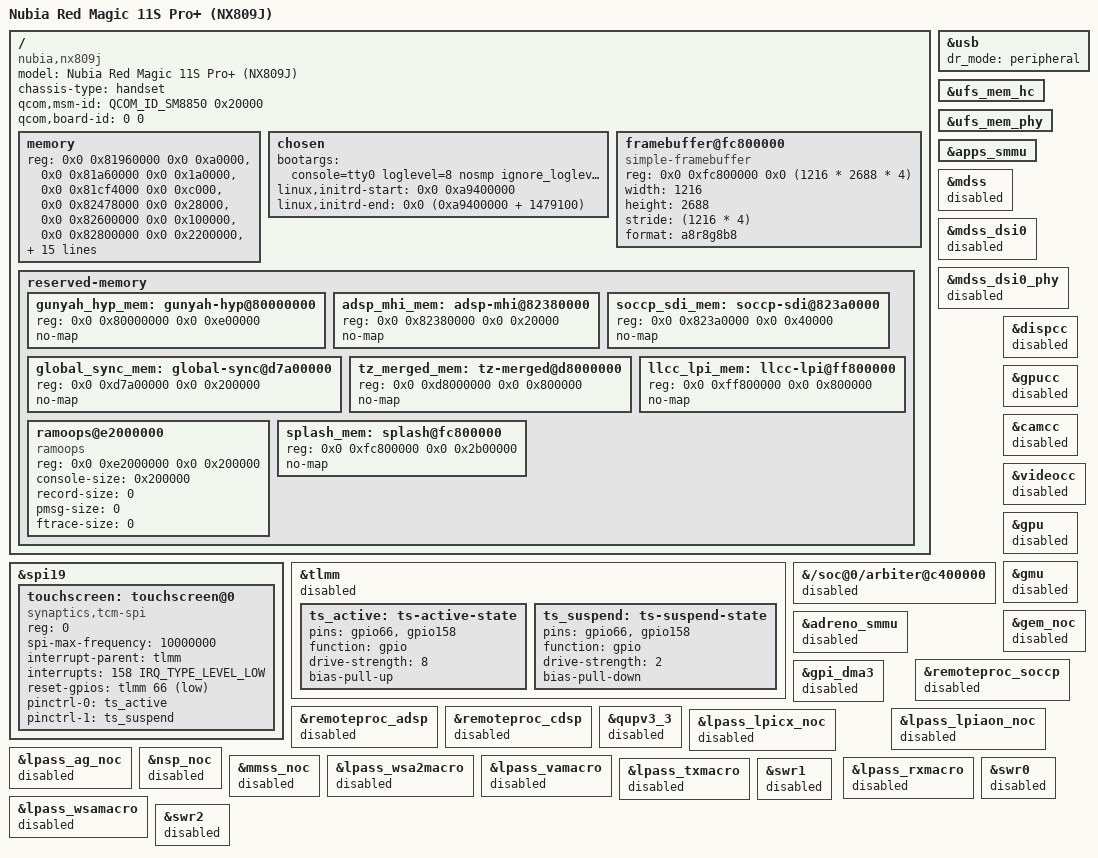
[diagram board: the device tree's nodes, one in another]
// SPDX-License-Identifier: BSD-3-Clause
/*
 * Copyright (c) 2026 Nubia / ZTE. All rights reserved.
 *
 * Nubia Red Magic 11S Pro+ (NX809J)
 * SoC: Qualcomm SM8850 (mainline codename: kaanapali)
 */

/dts-v1/;

#include <dt-bindings/arm/qcom,ids.h>
#include <dt-bindings/gpio/gpio.h>
#include <dt-bindings/interrupt-controller/irq.h>
#include "kaanapali-mtp.dts"

/*
 * No PSCI probe on this phone.
 *
 * kaanapali.dtsi declares a PSCI node with method = "smc". The vendor
 * devicetree for this board has no /psci node at all: the bootloader starts
 * Gunyah as the hypervisor and Android runs as a guest whose PSCI comes from
 * Gunyah over HVC - the tree carries /hypervisor with
 * "qcom,gunyah-hypervisor-1.0" plus a "qcom,gunyah-vm" child instead. Probing
 * the SMC conduit hands EL3 an SMC the firmware was never configured to
 * accept, and the answer to that is a reset into the vendor's memory dump,
 * before the kernel has printed a single line. Boot single core and leave the
 * secure monitor alone until we know what it does implement.
 */
/ {
	/delete-node/ psci;
};

/ {
	model = "Nubia Red Magic 11S Pro+ (NX809J)";
	compatible = "nubia,nx809j", "qcom,kaanapali-mtp", "qcom,kaanapali";

	chassis-type = "handset";

	/* Bootloader board selection - REQUIRED. Without these the bootloader
	 * cannot choose the correct board and does not bring the platform up.
	 * Mirrors the working kaanapali trees (oneplus-infiniti). */
	qcom,msm-id = <QCOM_ID_SM8850 0x20000>;	/* SM8850 v2.0 */
	qcom,board-id = <0 0>;

	/* /memory: filled by ABL when booting through ABL (the bootloader
	 * replaces /memory with the real usable-RAM map, so the ranges below
	 * cost nothing there), but U-Boot - the path this board is now brought
	 * up on - hands the kernel exactly the devicetree it loaded, so the
	 * ranges have to be here or the kernel has no RAM at all.
	 *
	 * They are ABL's own usable ranges, read back from this device
	 * (/sys/firmware/fdt on a stock Android boot) - not a guess.
	 *
	 * NOTE the 0xdfda0000 range: ABL reports it as one run up to
	 * 0xff800000, but the splash carve-out [0xfc800000, 0xff300000) is
	 * split OUT here instead of merely being covered by reserved-memory.
	 * simplefb does request_mem_region() on its framebuffer, and a region
	 * that sits inside the busy "System RAM" iomem resource fails that
	 * request with -EBUSY - so the console would silently never appear.
	 * Keeping the framebuffer out of /memory also guarantees nothing
	 * allocates over the buffer the DPU is still scanning. */
	memory {
		device_type = "memory";
		reg = <0x0 0x81960000 0x0 0xa0000>,
		      <0x0 0x81a60000 0x0 0x1a0000>,
		      <0x0 0x81cf4000 0x0 0xc000>,
		      <0x0 0x82478000 0x0 0x28000>,
		      <0x0 0x82600000 0x0 0x100000>,
		      <0x0 0x82800000 0x0 0x2200000>,
		      <0x0 0x8a980000 0x0 0x80000>,
		      <0x0 0x9959c000 0x0 0x64000>,
		      <0x0 0x9ce80000 0x0 0x2e00000>,
		      <0x0 0x9ffe0000 0x0 0x70000>,
		      <0x0 0xa0910000 0x0 0xa70000>,
		      <0x0 0xa5a00000 0x0 0x2f423000>,
		      <0x0 0xd5100000 0x0 0x2700000>,
		      <0x0 0xd79c0000 0x0 0x40000>,
		      <0x0 0xd7c00000 0x0 0x400000>,
		      <0x0 0xdfda0000 0x0 0x1ca60000>,	/* .. 0xfc800000 */
		      <0x0 0xff300000 0x0 0x500000>,	/* 0xff300000 .. 0xff800000 */
		      <0x8 0x80000000 0x0 0x2f6fd000>,
		      <0x8 0xb0000000 0x0 0x8500000>,
		      <0x8 0xc0000000 0x1 0x40000000>,
		      <0xa 0x0 0x2 0x0>;
	};

	/* Console. ABL leaves the DPU scanning out of the splash buffer, and
	 * with the display subsystem forced off below neither U-Boot nor this
	 * kernel ever reprograms MDSS, so the buffer stays live on the panel.
	 * simple-framebuffer lets the kernel draw its log straight into it:
	 * CONFIG_FB_SIMPLE maps the region, fbdev gives us fb0 and fbcon binds
	 * to it, so `console=tty1` puts the entire printk log - including
	 * everything buffered before fbcon came up, which the console layer
	 * replays on registration - on the only screen this board has.
	 *
	 * Deliberately NO clocks property. The reference tree's note that
	 * simplefb "does not work here" is about simplefb's own clock handling
	 * (clk_prepare_enable on display clocks whose power island is down) and
	 * about the msm_mdss reset path - neither of which applies to a plain
	 * pixel buffer that the bootloader already programmed and is already
	 * scanning out. */
	chosen {
		#address-cells = <2>;
		#size-cells = <2>;
		ranges;

		/* Baked in here because the EFI bootloader (bl/nx809j-boot.c in
		 * the build repo) deliberately does not parse or patch FDTs: it
		 * copies this devicetree, the kernel and the initramfs to fixed
		 * addresses and branches to the kernel with x0 pointing here.
		 * Keep the addresses in sync with that file. */
		bootargs = "console=tty0 loglevel=8 nosmp ignore_loglevel keep_bootcon initcall_debug initcall_blacklist=clk_disable_unused,genpd_power_off_unused,regulator_init_complete,of_platform_sync_state_init panic=0 oops=panic fw_devlink=off icc-rpmh.qos_disable=1";

		linux,initrd-start = <0x0 0xa9400000>;
		linux,initrd-end = <0x0 (0xa9400000 + 1479100)>;

	};
};

/ {
	framebuffer@fc800000 {
		compatible = "simple-framebuffer";
		reg = <0x0 0xfc800000 0x0 (1216 * 2688 * 4)>;
		width = <1216>;
		height = <2688>;
		stride = <(1216 * 4)>;
		format = "a8r8g8b8";
	};
};

/*
 * The framebuffer is a top level node on purpose: platform devices are created
 * for the children of the root node, but not for the children of /chosen on
 * arm64 - the helper that turns a /chosen/simple-framebuffer into a platform
 * device (SYSFB_SIMPLEFB) depends on X86 || EFI. With FB_SIMPLE=y built in
 * this node gives the kernel a real console on the panel from initcall time,
 * which is the only output channel this board has: the debug UART is not
 * wired out and the ABL leaves the panel scanning out of this very buffer.
 */

&spi19 {
	status = "okay";

	touchscreen: touchscreen@0 {
		compatible = "synaptics,tcm-spi";
		reg = <0>;
		spi-max-frequency = <10000000>;

		interrupt-parent = <&tlmm>;
		interrupts = <158 IRQ_TYPE_LEVEL_LOW>;

		reset-gpios = <&tlmm 66 GPIO_ACTIVE_LOW>;

		pinctrl-0 = <&ts_active>;
		pinctrl-1 = <&ts_suspend>;
		pinctrl-names = "default", "sleep";

		status = "okay";
	};
};

/* Diagnostics: force peripheral role so the host sees enumeration as soon
 * as the controller probes, without waiting for pmic-glink CC logic. */
&usb {
	dr_mode = "peripheral";
};

&tlmm {
	/*
	 * The probe of pinctrl@f100000 never returns: with the probe-entry printk
	 * in place the log ends at "dd: ENTER f100000.pinctrl <- kaanapali-tlmm"
	 * with no matching "returned" line, and there is no oops, no abort and no
	 * lockup report - a silent bus stall, which is what a register access to
	 * the TLMM block looks like when the block is not up yet. msm_pinctrl_probe
	 * touches those registers almost immediately (msm_pinctrl_setup_pm_reset(),
	 * then registering 218 GPIOs) and the node carries no clocks, exactly like
	 * upstream sm8750, so nothing in the driver brings it up first.
	 *
	 * Disabled to find out what is behind it. The console is the simplefb on
	 * the panel and does not need pinctrl, so the log channel survives, and
	 * anything that does need a pin state will simply defer instead of hanging.
	 * Re-enable this once the block is known to be powered up at probe time.
	 */
	status = "disabled";

	ts_active: ts-active-state {
		pins = "gpio66", "gpio158";
		function = "gpio";
		drive-strength = <8>;
		bias-pull-up;
	};

	ts_suspend: ts-suspend-state {
		pins = "gpio66", "gpio158";
		function = "gpio";
		drive-strength = <2>;
		bias-pull-down;
	};
};

/* Persistent console log shared with the Android side (same physical
 * region the stock OS uses); read failures back from Android via:
 *   /sys/fs/pstore/console-ramoops-0
 */
/ {
	reserved-memory {
		#address-cells = <2>;
		#size-cells = <2>;

		/* Gunyah / TZ / XBL / SoCCP runtime regions that our
		 * kaanapali.dtsi does NOT declare but the firmware actively
		 * uses. Missing any of these causes the kernel to allocate
		 * over hypervisor/TZ code -> exception -> ZTE Memory Dump.
		 * Addresses copied from map220v's working kaanapali tree. */
		gunyah_hyp_mem: gunyah-hyp@80000000 {
			reg = <0x0 0x80000000 0x0 0xe00000>;
			no-map;
		};

		adsp_mhi_mem: adsp-mhi@82380000 {
			reg = <0x0 0x82380000 0x0 0x20000>;
			no-map;
		};

		soccp_sdi_mem: soccp-sdi@823a0000 {
			reg = <0x0 0x823a0000 0x0 0x40000>;
			no-map;
		};

		global_sync_mem: global-sync@d7a00000 {
			reg = <0x0 0xd7a00000 0x0 0x200000>;
			no-map;
		};

		tz_merged_mem: tz-merged@d8000000 {
			reg = <0x0 0xd8000000 0x0 0x800000>;
			no-map;
		};

		llcc_lpi_mem: llcc-lpi@ff800000 {
			reg = <0x0 0xff800000 0x0 0x800000>;
			no-map;
		};

		ramoops@e2000000 {
			compatible = "ramoops";
			reg = <0x0 0xe2000000 0x0 0x200000>;

			console-size = <0x200000>;
			record-size = <0>;
			pmsg-size = <0>;
			ftrace-size = <0>;
		};

		/* The bootloader's splash / console buffer, the one the DPU is
		 * scanning out of and the one our /chosen framebuffer points at.
		 * Belt and braces on top of splitting it out of /memory above:
		 * `no-map` also keeps it out of the linear map, so the kernel
		 * cannot touch it through a stray pointer either. Needed in its
		 * own right on the ABL boot path, where the bootloader replaces
		 * /memory and this carve-out would otherwise be allocated. */
		splash_mem: splash@fc800000 {
			reg = <0x0 0xfc800000 0x0 0x2b00000>;
			no-map;
		};
	};
};

/* ===== Bring-up: get to a shell first, then add hardware back =====
 *
 * Every iteration so far has moved the hang a little further along - 0.25 s,
 * then 0.96 s of kernel time - and each one costs a build, a fastboot dance and
 * a five second window in which the panel shows the log before the reset
 * replaces it. That is a slow way to port a platform.
 *
 * So take the other road: take out the late hardware that is most likely to
 * hang and that nothing in early boot needs, reach the initramfs shell on the
 * panel, and re-enable things one at a time from there. A live shell also means
 * the kernel is not stuck, so the APSS watchdog keeps being petted and the
 * device stops resetting into the vendor memory-dump screen at all.
 *
 * UFS: the reference U-Boot port needed a dedicated hyp-SMMU driver before UFS
 * would transfer anything on this SoC, and this kernel has CONFIG_SCSI_UFS_QCOM
 * built in with the same SMMU in the path. The initramfs does not need it - its
 * log sinks fail gracefully and it drops to a shell regardless.
 *
 * apps_smmu: on Qualcomm phones the SMMU is brought up by firmware, partly
 * emulated by the hypervisor, and cannot be turned off. The U-Boot side of this
 * port needed its own qcom-hyp-smmu driver for exactly that reason, and
 * CONFIG_ARM_SMMU_DISABLE_BYPASS_BY_DEFAULT=y means a single unmapped stream
 * takes a fault rather than passing through. */
&ufs_mem_hc {
	/*
	 * Back on. UFS and its SMMU were switched off early in the bisect, when
	 * everything was still a suspect; the two rounds of probe-entry logging have
	 * since named the real blockers (the tlmm probe, then the "switch off what
	 * is unused" initcalls), so they were never the problem.
	 *
	 * They are needed for more than storage: with no UFS there are no block
	 * devices at all, so nothing in the initramfs can persist the kernel log -
	 * both of /data and the boot_b FAT mount attempts fail and the run has to be
	 * read off the panel again. Storage is what makes the log machine-readable,
	 * and the log is what makes every later step cheap.
	 */
	status = "okay";
};

&ufs_mem_phy {
	status = "okay";
};

&apps_smmu {
	/* The UFS host sits behind this SMMU, so the two are re-enabled together. */
	status = "okay";
};

/* ===== Bring-up bisect: force-off the display subsystem =====
 * kaanapali-mtp.dts enables &mdss and hangs a panel off &mdss_dsi0, so
 * drm/msm probes MDSS at boot. On this board that is exactly the path the
 * working kaanapali trees warn about: the DPU is live on the scanout the
 * bootloader set up, and msm_mdss_enable() / the MDSS power-domain and NoC
 * transitions on an already-running pipeline stall (AXI/NoC), which is a
 * silent hang - no console, no reset.
 *
 * We do not need it: the panel console comes from the simple-framebuffer in
 * /chosen, which only writes pixels into the buffer ABL is already
 * scanning. Force the whole chain off so nothing touches MDSS or dispcc's
 * power islands during bring-up. */
&mdss {
	status = "disabled";
};

&mdss_dsi0 {
	status = "disabled";
};

&mdss_dsi0_phy {
	status = "disabled";
};

/* ===== Bring-up bisect: force-off the SPMI PMIC bus =====
 *
 * The board DT declares the arbiter as
 *
 *     compatible = "qcom,kaanapali-spmi-pmic-arb", "qcom,glymur-spmi-pmic-arb"
 *
 * and mainline's drivers/spmi/spmi-pmic-arb.c knows only qcom,spmi-pmic-arb,
 * qcom,x1e80100-spmi-pmic-arb and qcom,glymur-spmi-pmic-arb - so it binds
 * through the glymur fallback, whose register layout is not kaanapali's. The
 * node's reg/reg-names do match the device's own stock devicetree exactly, so
 * this is not a missing-property problem: the arbiter registers, the transfers
 * are wrong. Which is what the log shows, right before the kernel stops:
 *
 *     pmic-spmi ...: probe with driver pmic-spmi failed with error -5
 *
 * drivers/mfd/qcom-spmi-pmic.c reading PMIC revision IDs over that bus gets
 * -EIO, and an SPMI access that waits for a completion bit that never arrives
 * hangs instead - so the kernel stops, and a watchdog reset replaces the panel
 * with the vendor memory-dump screen about thirty seconds later.
 *
 * Nothing reachable on this bus is needed to get to a console: the regulators
 * come from RPMh (/soc@0/rsc@18900000/regulators-0..8), not from SPMI. Disable
 * the arbiter and everything hanging off it (RTC, pwrkey, PMIC GPIOs, thermal
 * alarms) until the drivers can be fixed for kaanapali. */
&{/soc@0/arbiter@c400000} {
	status = "disabled";
};

/* ===== Bring-up bisect: force-off the clock controllers that live in
 * powered-down power islands =====
 *
 * This is the same failure class as the NoC QoS one below, and it is worse:
 * of_clk_init() runs from start_kernel() *before* console_init(), so anything
 * that raises a synchronous external abort there kills the boot before a single
 * line of the console exists - no framebuffer console, no pstore, nothing on
 * the panel but U-Boot's own teardown text. That is exactly the shape of the
 * current failure (black, then the vendor memory-dump screen).
 *
 * VIDEO_CC, GPU_CC, CAM_CC and DISP_CC each sit behind a GDSC that is off at
 * boot: nothing has powered the video, GPU, camera or display island. Their
 * qcom_cc_probe() writes branch and PLL registers, so the first access can
 * abort. None of them is needed to reach a console: MDSS is already off, the
 * GPU is off, and there is no camera or video bring-up here yet.
 *
 * GCC (the always-on top-level controller), TCSR and the RPMh clock output stay
 * enabled - UFS and the rest of the platform need them. */
&dispcc {
	status = "disabled";
};

&gpucc {
	status = "disabled";
};

&camcc {
	status = "disabled";
};

&videocc {
	status = "disabled";
};

/* ===== Bring-up bisect: force-off the GPU subsystem =====
 * kaanapali-gpu.dtsi (from a non-mainline lore series, Adreno 840
 * chip_id 44050a01) leaves gpu/gmu/adreno_smmu with NO status, so they
 * default to "okay" and the msm/adreno + arm-smmu drivers probe them at
 * boot. This tree has no working Adreno 840 mainline catalog, and
 * CONFIG_ARM_SMMU_DISABLE_BYPASS_BY_DEFAULT yields a fault on the first
 * unmapped SMMU access. Black-screen-then-Memory-Dump is consistent with
 * the GPU/SMMU probe faulting before any console output. We don't need
 * the GPU to reach a console, so force it off for the bisect.
 */
&gpu {
	status = "disabled";
};

&gmu {
	status = "disabled";
};

&adreno_smmu {
	status = "disabled";
};

/* ===== Bring-up: no NoC provider, and no remoteproc =====
 *
 * The initcall_debug + dyndbg log ends on a run of successful interconnect
 * probes -
 *
 *     probe of 16e0000.interconnect with driver qnoc-kaanapali returned 0
 *     probe of 17?0000.interconnect with driver qnoc-kaanapali returned 0
 *
 * and then nothing at all, which is what a hang looks like: the next device's
 * probe never returns and never prints. In devicetree order the next NoC after
 * aggre_noc is mmss_noc (disabled above), then the lpass and nsp ones
 * (disabled), and finally gem_noc - the last provider left that sits behind a
 * power island nothing has powered.
 *
 * So take out every remaining NoC provider. They are only needed for
 * bandwidth voting; with UFS, the display and the DSPs all off there is nothing
 * left that needs a vote, and disabling the providers means the deferred-probe
 * phase stops walking into dead register space. A side effect worth having: no
 * 'interconnect' line in the log at all identifies this build.
 *
 * The remoteprocs go the same way: each one asks the TZ (over SCM) to
 * authenticate firmware and then waits for the DSP to answer over GLINK. Both
 * are waits on something outside the AP, and none of ADSP, CDSP or SoCCP is
 * needed to reach an initramfs shell. */
&gem_noc {
	status = "disabled";
};

&remoteproc_soccp {
	status = "disabled";
};

&remoteproc_adsp {
	status = "disabled";
};

&remoteproc_cdsp {
	status = "disabled";
};

/* ===== Bring-up: the next two devices the deferred list walks into =====
 *
 * With the NoC providers gone the log gets past the interconnect probes and
 * stops after aggre_noc instead - which is where the devicetree puts these:
 *
 *     dma-controller@1900000   gpi_dma3   (okay)
 *     geniqup@19c0000          qupv3_3    (okay, and every child disabled)
 *
 * They are the only GENI/QUP nodes still enabled that sit right there in file
 * order: gpi_dma1/gpi_dma2 and qupv3_1/qupv3_2 come earlier in the dtsi and the
 * log already walked past them to reach the NoCs, so those two wrappers are
 * what the deferred probe is about to touch.
 *
 * Both are firmware/clock/interconnect consumers - GPI DMA has firmware loaded
 * through the TZ, the QUP wrapper needs its clocks and an interconnect path -
 * and neither is needed here: there are no UART pads on this board and nothing
 * on i2c or spi that early boot wants. */
&gpi_dma3 {
	status = "disabled";
};

&qupv3_3 {
	status = "disabled";
};

/* ===== NoC QoS bring-up fix (boot-killer without it) =====
 * The static QoS MMIO of the LPASS/MMSS/NSP NoC providers lives in power
 * islands that are NOT up during early boot. When such a provider probes,
 * qcom_icc_set_qos() writes its QoS registers -> synchronous external abort
 * (SEA) -> the boot dies. This is documented in the working kaanapali trees
 * ("probing it now causes a sync external abort in qcom_icc_rpmh_configure_qos()").
 *
 * The LPASS providers exist only for audio, which is not needed for bring-up,
 * so disable them together with the audio codecs / soundwire (the MTP board
 * pulls all of those in). NSP is compute-only -> off too. The MMSS NoC is the
 * MDP0->EBI1 provider for the display and stays enabled; the global QoS
 * programming is additionally skipped at runtime by the `icc-rpmh.qos_disable=1`
 * boot argument (see drivers/interconnect/qcom/icc-rpmh.c).
 */
&lpass_lpiaon_noc {
	status = "disabled";
};

&lpass_lpicx_noc {
	status = "disabled";
};

&lpass_ag_noc {
	status = "disabled";
};

&nsp_noc {
	status = "disabled";
};

&mmss_noc {
	/*
	 * Was forced okay during the display bring-up attempt; the display is
	 * off now (see the MDSS block above), so there is no reason to keep it.
	 *
	 * MMSS_NOC is one of the NoC providers whose registers sit behind a
	 * power domain that nothing has powered: DISP_CC and MDSS are disabled,
	 * so the MMSS island is off, and the provider's probe - which programs
	 * QoS and BCM registers - is a bus access into a dead island. That is
	 * the same failure class the working kaanapali trees warn about, and it
	 * is where the kernel now stops: with initcall_debug and dyndbg the last
	 * unpaired initcall is deferred_probe_initcall, and the last successful
	 * probes are the interconnect ones (icc-bcm-voter, on interconnect@...).
	 */
	status = "disabled";
};

/* Audio path (needs the LPASS islands above) - off for bring-up. */
&lpass_wsa2macro {
	status = "disabled";
};

&lpass_vamacro {
	status = "disabled";
};

&lpass_rxmacro {
	status = "disabled";
};

&lpass_txmacro {
	status = "disabled";
};

&lpass_wsamacro {
	status = "disabled";
};

&swr0 {
	status = "disabled";
};

&swr1 {
	status = "disabled";
};

&swr2 {
	status = "disabled";
};
